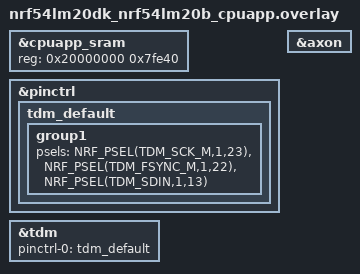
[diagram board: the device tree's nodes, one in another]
/*
 * Copyright (c) 2026 Nordic Semiconductor ASA
 *
 * SPDX-License-Identifier: LicenseRef-Nordic-5-Clause
 */

 #include <dt-bindings/pinctrl/nrf-pinctrl.h>

/*
 * 3x ICS-52000 TDM daisy chain (left / center / right):
 *   all SCK      -> P1.23  (TDM_SCK_M)
 *   all SD       -> P1.13  (TDM_SDIN), plus ~100k pulldown to GND
 *   nRF P1.22    -> WS  of left mic   (TDM_FSYNC_M, slot 0)
 *   left   WSO   -> WS  of center mic (slot 1)
 *   center WSO   -> WS  of right mic  (slot 2)
 *   right  WSO   -> not connected
 *   VDD -> 3V3, GND -> GND
 */

&cpuapp_sram {
	reg = <0x20000000 0x7fe40>;
	ranges = <0x0 0x20000000 0x7fe40>;
};

&pinctrl {
	tdm_default: tdm_default {
		group1 {
			psels = <NRF_PSEL(TDM_SCK_M,1,23)>,
				<NRF_PSEL(TDM_FSYNC_M,1,22)>,
				<NRF_PSEL(TDM_SDIN,1,13)>;
		};
	};
};

&tdm {
	status = "okay";
	pinctrl-0 = <&tdm_default>;
	pinctrl-names = "default";
};

&axon {
	status = "okay";
};
